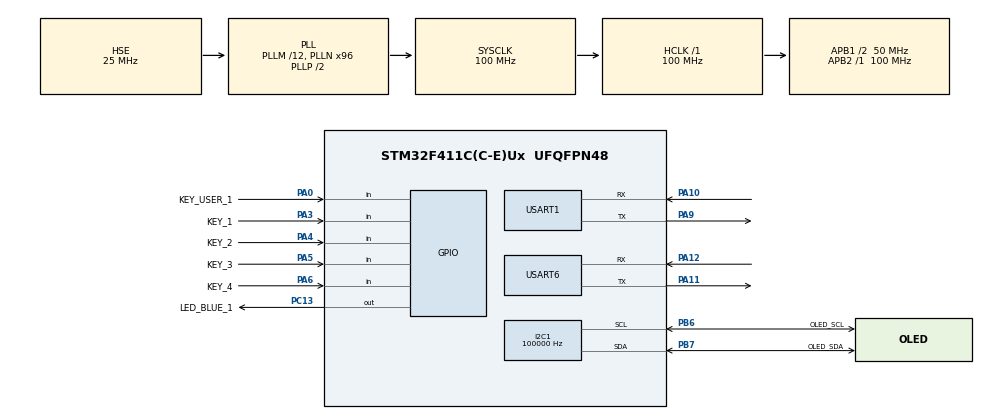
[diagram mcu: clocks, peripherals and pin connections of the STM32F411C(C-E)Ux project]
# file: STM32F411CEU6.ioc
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Dma.I2C1_TX.0.Direction=DMA_MEMORY_TO_PERIPH
Dma.I2C1_TX.0.FIFOMode=DMA_FIFOMODE_DISABLE
Dma.I2C1_TX.0.Instance=DMA1_Stream1
Dma.I2C1_TX.0.MemDataAlignment=DMA_MDATAALIGN_BYTE
Dma.I2C1_TX.0.MemInc=DMA_MINC_ENABLE
Dma.I2C1_TX.0.Mode=DMA_NORMAL
Dma.I2C1_TX.0.PeriphDataAlignment=DMA_PDATAALIGN_BYTE
Dma.I2C1_TX.0.PeriphInc=DMA_PINC_DISABLE
Dma.I2C1_TX.0.Priority=DMA_PRIORITY_LOW
Dma.Request0=I2C1_TX
Dma.Request1=USART6_RX
Dma.USART6_RX.1.Direction=DMA_PERIPH_TO_MEMORY
Dma.USART6_RX.1.FIFOMode=DMA_FIFOMODE_DISABLE
Dma.USART6_RX.1.Instance=DMA2_Stream1
Dma.USART6_RX.1.MemDataAlignment=DMA_MDATAALIGN_BYTE
Dma.USART6_RX.1.MemInc=DMA_MINC_ENABLE
Dma.USART6_RX.1.Mode=DMA_CIRCULAR
Dma.USART6_RX.1.PeriphDataAlignment=DMA_PDATAALIGN_BYTE
Dma.USART6_RX.1.PeriphInc=DMA_PINC_DISABLE
Dma.USART6_RX.1.Priority=DMA_PRIORITY_LOW
FREERTOS.Tasks01=defaultTask,24,128,StartDefaultTask,Default,NULL,Dynamic,NULL,NULL
I2C1.ClockSpeed=100000
I2C1.I2C_Mode=I2C_Fast
Mcu.Family=STM32F4
Mcu.Name=STM32F411C(C-E)Ux
Mcu.Package=UFQFPN48
NVIC.DMA1_Stream1_IRQn=true\:5\:0\:false\:false\:true\:true\:false\:true\:true
NVIC.DMA2_Stream1_IRQn=true\:5\:0\:false\:false\:true\:true\:false\:true\:true
NVIC.I2C1_EV_IRQn=true\:5\:0\:false\:false\:true\:true\:true\:true\:true
NVIC.PriorityGroup=NVIC_PRIORITYGROUP_4
NVIC.USART1_IRQn=true\:5\:0\:false\:false\:true\:true\:true\:true\:true
NVIC.USART6_IRQn=true\:5\:0\:false\:false\:true\:true\:true\:true\:true
PA0-WKUP.GPIO_Label=KEY_USER_1
PA0-WKUP.GPIO_PuPd=GPIO_PULLUP
PA0-WKUP.Signal=GPIO_Input
PA10.Mode=Asynchronous
PA10.Signal=USART1_RX
PA11.Mode=Asynchronous
PA11.Signal=USART6_TX
PA12.Mode=Asynchronous
PA12.Signal=USART6_RX
PA3.GPIO_Label=KEY_1
PA3.GPIO_PuPd=GPIO_PULLUP
PA3.Signal=GPIO_Input
PA4.GPIO_Label=KEY_2
PA4.GPIO_PuPd=GPIO_PULLUP
PA4.Signal=GPIO_Input
PA5.GPIO_Label=KEY_3
PA5.GPIO_PuPd=GPIO_PULLUP
PA5.Signal=GPIO_Input
PA6.GPIO_Label=KEY_4
PA6.GPIO_PuPd=GPIO_PULLUP
PA6.Signal=GPIO_Input
PA9.Mode=Asynchronous
PA9.Signal=USART1_TX
PB6.GPIO_Label=OLED_SCL
PB6.Mode=I2C
PB6.Signal=I2C1_SCL
PB7.GPIO_Label=OLED_SDA
PB7.Mode=I2C
PB7.Signal=I2C1_SDA
PC13-ANTI_TAMP.GPIO_Label=LED_BLUE_1
PC13-ANTI_TAMP.GPIO_ModeDefaultOutputPP=GPIO_MODE_OUTPUT_PP
PC13-ANTI_TAMP.GPIO_PuPd=GPIO_PULLUP
PC13-ANTI_TAMP.GPIO_Speed=GPIO_SPEED_FREQ_LOW
PC13-ANTI_TAMP.PinState=GPIO_PIN_SET
PC13-ANTI_TAMP.Signal=GPIO_Output
PC14-OSC32_IN.Mode=LSE-External-Oscillator
PC14-OSC32_IN.Signal=RCC_OSC32_IN
PC15-OSC32_OUT.Mode=LSE-External-Oscillator
PC15-OSC32_OUT.Signal=RCC_OSC32_OUT
PH0\ -\ OSC_IN.Mode=HSE-External-Oscillator
PH0\ -\ OSC_IN.Signal=RCC_OSC_IN
PH1\ -\ OSC_OUT.Mode=HSE-External-Oscillator
PH1\ -\ OSC_OUT.Signal=RCC_OSC_OUT
ProjectManager.HeapSize=0x200
ProjectManager.StackSize=0x400
ProjectManager.TargetToolchain=MDK-ARM V5.32
RCC.48MHZClocksFreq_Value=50000000
RCC.AHBFreq_Value=100000000
RCC.APB1CLKDivider=RCC_HCLK_DIV2
RCC.APB1Freq_Value=50000000
RCC.APB1TimFreq_Value=100000000
RCC.APB2Freq_Value=100000000
RCC.APB2TimFreq_Value=100000000
RCC.CortexFreq_Value=100000000
RCC.HCLKFreq_Value=100000000
RCC.HSE_VALUE=25000000
RCC.HSI_VALUE=16000000
RCC.PLLM=12
RCC.PLLN=96
RCC.PLLSourceVirtual=RCC_PLLSOURCE_HSE
RCC.SYSCLKFreq_VALUE=100000000
RCC.SYSCLKSource=RCC_SYSCLKSOURCE_PLLCLK
RCC.VCOOutputFreq_Value=200000000
USART1.VirtualMode=VM_ASYNC
USART6.VirtualMode=VM_ASYNC
VP_FREERTOS_VS_CMSIS_V2.Mode=CMSIS_V2
VP_IWDG_VS_IWDG.Mode=IWDG_Activate
board=custom

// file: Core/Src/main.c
/* USER CODE BEGIN Header */
/**
  ******************************************************************************
  * @file           : main.c
  * @brief          : Main program body
  ******************************************************************************
  * @attention
  *
  * Copyright (c) 2025 STMicroelectronics.
  * All rights reserved.
  *
  * This software is licensed under terms that can be found in the LICENSE file
  * in the root directory of this software component.
  * If no LICENSE file comes with this software, it is provided AS-IS.
  *
  ******************************************************************************
  */
/* USER CODE END Header */
#include "main.h"
#include "cmsis_os.h"
#include "dma.h"
#include "i2c.h"
#include "iwdg.h"
#include "usart.h"
#include "gpio.h"

void SystemClock_Config(void);
void MX_FREERTOS_Init(void);

int main(void)
{

  /* USER CODE BEGIN 1 */
	__enable_irq();								/**< 开启全局中断 */

  /* USER CODE END 1 */

  /* MCU Configuration--------------------------------------------------------*/

  /* Reset of all peripherals, Initializes the Flash interface and the Systick. */
  HAL_Init();

  /* Configure the system clock */
  SystemClock_Config();

  /* Initialize all configured peripherals */
  MX_GPIO_Init();
  MX_DMA_Init();
  MX_USART1_UART_Init();
  MX_IWDG_Init();
  MX_I2C1_Init();
  MX_USART6_UART_Init();

  /* Init scheduler */
  osKernelInitialize();

  /* Call init function for freertos objects (in cmsis_os2.c) */
  MX_FREERTOS_Init();

  /* Start scheduler */
  osKernelStart();

  /* We should never get here as control is now taken by the scheduler */

  /* Infinite loop */
  while (1)
  {

  }
}

void SystemClock_Config(void)
{
  RCC_OscInitTypeDef RCC_OscInitStruct = {0};
  RCC_ClkInitTypeDef RCC_ClkInitStruct = {0};

  /** Configure the main internal regulator output voltage
  */
  __HAL_RCC_PWR_CLK_ENABLE();
  __HAL_PWR_VOLTAGESCALING_CONFIG(PWR_REGULATOR_VOLTAGE_SCALE1);

  /** Initializes the RCC Oscillators according to the specified parameters
  * in the RCC_OscInitTypeDef structure.
  */
  RCC_OscInitStruct.OscillatorType = RCC_OSCILLATORTYPE_LSI|RCC_OSCILLATORTYPE_HSE;
  RCC_OscInitStruct.HSEState = RCC_HSE_ON;
  RCC_OscInitStruct.LSIState = RCC_LSI_ON;
  RCC_OscInitStruct.PLL.PLLState = RCC_PLL_ON;
  RCC_OscInitStruct.PLL.PLLSource = RCC_PLLSOURCE_HSE;
  RCC_OscInitStruct.PLL.PLLM = 12;
  RCC_OscInitStruct.PLL.PLLN = 96;
  RCC_OscInitStruct.PLL.PLLP = RCC_PLLP_DIV2;
  RCC_OscInitStruct.PLL.PLLQ = 4;
  if (HAL_RCC_OscConfig(&RCC_OscInitStruct) != HAL_OK)
  {
    Error_Handler();
  }

  /** Initializes the CPU, AHB and APB buses clocks
  */
  RCC_ClkInitStruct.ClockType = RCC_CLOCKTYPE_HCLK|RCC_CLOCKTYPE_SYSCLK
                              |RCC_CLOCKTYPE_PCLK1|RCC_CLOCKTYPE_PCLK2;
  RCC_ClkInitStruct.SYSCLKSource = RCC_SYSCLKSOURCE_PLLCLK;
  RCC_ClkInitStruct.AHBCLKDivider = RCC_SYSCLK_DIV1;
  RCC_ClkInitStruct.APB1CLKDivider = RCC_HCLK_DIV2;
  RCC_ClkInitStruct.APB2CLKDivider = RCC_HCLK_DIV1;

  if (HAL_RCC_ClockConfig(&RCC_ClkInitStruct, FLASH_LATENCY_3) != HAL_OK)
  {
    Error_Handler();
  }
}

void Error_Handler(void)
{
  __disable_irq();
  while (1)
  {
  }
}
